AUTOSAR XML (schema 4-2-2)
package /ComponentTypes
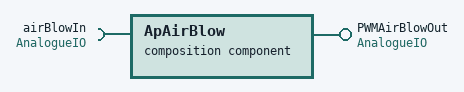
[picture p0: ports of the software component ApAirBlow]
  composition sw component type ApAirBlow
    require port airBlowIn: required-interface=AnalogueIO
    provide port PWMAirBlowOut: provided-interface=AnalogueIO
    component AirBlow: type=AirBlowController
    delegate AirBlow.airBlowIn <-> outer port airBlowIn
    delegate AirBlow.AirBlowOut <-> outer port PWMAirBlowOut
